# F28x7x_dma_regs register map
Vendor: Texas Instruments
Peripheral module from a debugger description file (folder C2000).
Address unit: 16 bits
Registers are 16-bit, read-write, no defined reset value unless marked. A register's access mark holds for its fields unless they carry their own. Offsets are as the file gives them; lines under a group give offsets from that group; [hi:lo] are bit positions; {n}, {i} and the like mark numbered series; 'fields as' and 'values as' point back to an identical list; <NAME> marks a mode.

## DMA_REGS — DMA Registers
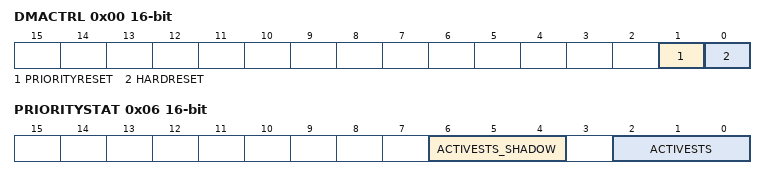
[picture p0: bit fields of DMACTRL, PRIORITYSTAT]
0x00 DMACTRL access not given — DMA Control Register
  [1] PRIORITYRESET — Priority Reset Bit (access R=0/W=1)
  [0] HARDRESET — Hard Reset Bit (access R=0/W=1)
0x01 DEBUGCTRL — Debug Control Register
  [15] FREE — Debug Mode Bit
0x04 PRIORITYCTRL1 — Priority Control 1 Register
  [0] CH1PRIORITY — Ch1 Priority Bit
0x06 PRIORITYSTAT ro — Priority Status Register
  [6:4] ACTIVESTS_SHADOW — Active Channel Status Shadow Bits
  [2:0] ACTIVESTS — Active Channel Status Bits
